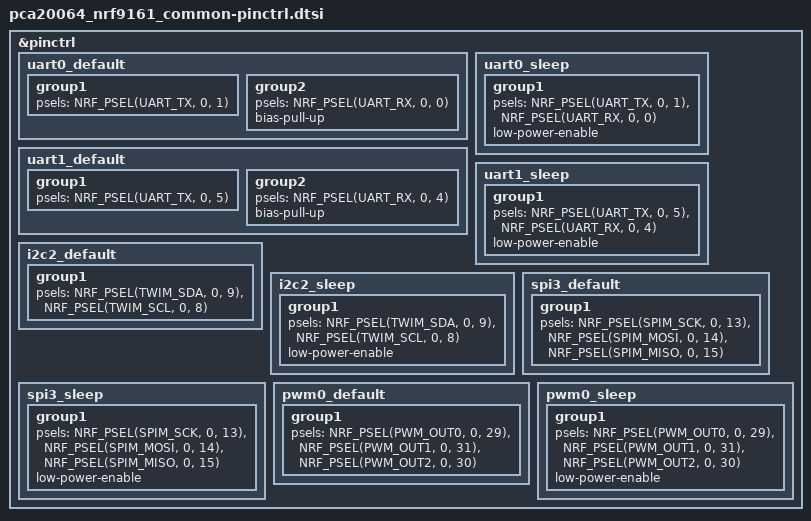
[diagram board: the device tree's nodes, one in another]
/*
 * Copyright (c) 2026
 * SPDX-License-Identifier: LicenseRef-Nordic-5-Clause
 */

&pinctrl {
	/* Measured PCA20064 routing: UART0 is VCOM0, UART1 is VCOM1. */
	uart0_default: uart0_default {
		group1 {
			psels = <NRF_PSEL(UART_TX, 0, 1)>;
		};
		group2 {
			psels = <NRF_PSEL(UART_RX, 0, 0)>;
			bias-pull-up;
		};
	};

	uart0_sleep: uart0_sleep {
		group1 {
			psels = <NRF_PSEL(UART_TX, 0, 1)>,
				<NRF_PSEL(UART_RX, 0, 0)>;
			low-power-enable;
		};
	};

	uart1_default: uart1_default {
		group1 {
			psels = <NRF_PSEL(UART_TX, 0, 5)>;
		};
		group2 {
			psels = <NRF_PSEL(UART_RX, 0, 4)>;
			bias-pull-up;
		};
	};

	uart1_sleep: uart1_sleep {
		group1 {
			psels = <NRF_PSEL(UART_TX, 0, 5)>,
				<NRF_PSEL(UART_RX, 0, 4)>;
			low-power-enable;
		};
	};

	i2c2_default: i2c2_default {
		group1 {
			psels = <NRF_PSEL(TWIM_SDA, 0, 9)>,
				<NRF_PSEL(TWIM_SCL, 0, 8)>;
		};
	};

	i2c2_sleep: i2c2_sleep {
		group1 {
			psels = <NRF_PSEL(TWIM_SDA, 0, 9)>,
				<NRF_PSEL(TWIM_SCL, 0, 8)>;
			low-power-enable;
		};
	};

	spi3_default: spi3_default {
		group1 {
			psels = <NRF_PSEL(SPIM_SCK, 0, 13)>,
				<NRF_PSEL(SPIM_MOSI, 0, 14)>,
				<NRF_PSEL(SPIM_MISO, 0, 15)>;
		};
	};

	spi3_sleep: spi3_sleep {
		group1 {
			psels = <NRF_PSEL(SPIM_SCK, 0, 13)>,
				<NRF_PSEL(SPIM_MOSI, 0, 14)>,
				<NRF_PSEL(SPIM_MISO, 0, 15)>;
			low-power-enable;
		};
	};

	pwm0_default: pwm0_default {
		group1 {
			psels = <NRF_PSEL(PWM_OUT0, 0, 29)>,
				<NRF_PSEL(PWM_OUT1, 0, 31)>,
				<NRF_PSEL(PWM_OUT2, 0, 30)>;
		};
	};

	pwm0_sleep: pwm0_sleep {
		group1 {
			psels = <NRF_PSEL(PWM_OUT0, 0, 29)>,
				<NRF_PSEL(PWM_OUT1, 0, 31)>,
				<NRF_PSEL(PWM_OUT2, 0, 30)>;
			low-power-enable;
		};
	};
};
